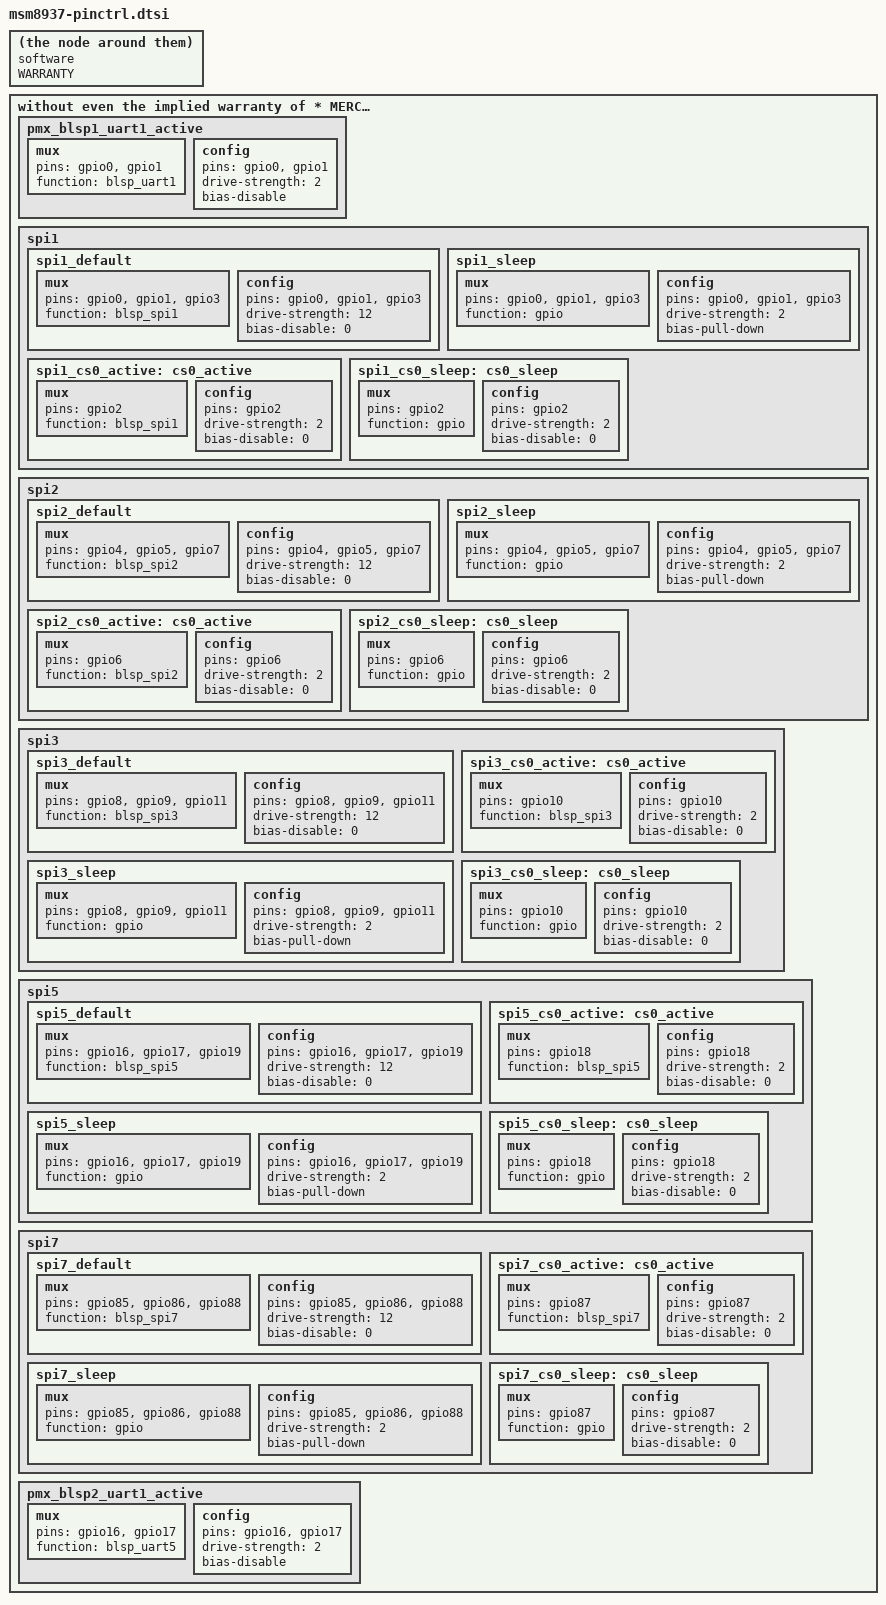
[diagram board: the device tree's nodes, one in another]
 * Copyright (c) 2015-2016, The Linux Foundation. All rights reserved.
 *
 * This program is free software; you can redistribute it and/or modify
 * it under the terms of the GNU General Public License version 2 and
 * only version 2 as published by the Free Software Foundation.
 *
 * This program is distributed in the hope that it will be useful,
 * but WITHOUT ANY WARRANTY; without even the implied warranty of
 * MERCHANTABILITY or FITNESS FOR A PARTICULAR PURPOSE.  See the
 * GNU General Public License for more details.
 */

&soc {
		pmx_blsp1_uart1_active: pmx_blsp1_uart1_active {
			mux {
				pins = "gpio0", "gpio1";
				function = "blsp_uart1";
			};

			config {
				pins = "gpio0", "gpio1";
				drive-strength = <2>;
				bias-disable;
			};
		};

		spi1 {
			spi1_default: spi1_default {
				/* active state */
				mux {
					/* MOSI, MISO, CLK */
					pins = "gpio0", "gpio1", "gpio3";
					function = "blsp_spi1";
				};

				config {
					pins = "gpio0", "gpio1", "gpio3";
					drive-strength = <12>; /* 12 MA */
					bias-disable = <0>; /* No PULL */
				};
			};

			spi1_sleep: spi1_sleep {
				/* suspended state */
				mux {
					/* MOSI, MISO, CLK */
					pins = "gpio0", "gpio1", "gpio3";
					function = "gpio";
				};

				config {
					pins = "gpio0", "gpio1", "gpio3";
					drive-strength = <2>; /* 2 MA */
					bias-pull-down; /* PULL Down */
				};
			};

			spi1_cs0_active: cs0_active {
				/* CS */
				mux {
					pins = "gpio2";
					function = "blsp_spi1";
				};

				config {
					pins = "gpio2";
					drive-strength = <2>;
					bias-disable = <0>;
				};
			};

			spi1_cs0_sleep: cs0_sleep {
				/* CS */
				mux {
					pins = "gpio2";
					function = "gpio";
				};

				config {
					pins = "gpio2";
					drive-strength = <2>;
					bias-disable = <0>;
				};
			};
		};

		spi2 {
			spi2_default: spi2_default {
				/* active state */
				mux {
					/* MOSI, MISO, CLK */
					pins = "gpio4", "gpio5", "gpio7";
					function = "blsp_spi2";
				};

				config {
					pins = "gpio4", "gpio5", "gpio7";
					drive-strength = <12>; /* 12 MA */
					bias-disable = <0>; /* No PULL */
				};
			};

			spi2_sleep: spi2_sleep {
				/* suspended state */
				mux {
					/* MOSI, MISO, CLK */
					pins = "gpio4", "gpio5", "gpio7";
					function = "gpio";
				};

				config {
					pins = "gpio4", "gpio5", "gpio7";
					drive-strength = <2>; /* 2 MA */
					bias-pull-down; /* PULL Down */
				};
			};

			spi2_cs0_active: cs0_active {
				/* CS */
				mux {
					pins = "gpio6";
					function = "blsp_spi2";
				};

				config {
					pins = "gpio6";
					drive-strength = <2>;
					bias-disable = <0>;
				};
			};

			spi2_cs0_sleep: cs0_sleep {
				/* CS */
				mux {
					pins = "gpio6";
					function = "gpio";
				};

				config {
					pins = "gpio6";
					drive-strength = <2>;
					bias-disable = <0>;
				};
			};
		};

		spi3 {
			spi3_default: spi3_default {
				/* active state */
				mux {
					/* MOSI, MISO, CLK */
					pins = "gpio8", "gpio9", "gpio11";
					function = "blsp_spi3";
				};

				config {
					pins = "gpio8", "gpio9", "gpio11";
					drive-strength = <12>; /* 12 MA */
					bias-disable = <0>; /* No PULL */
				};
			};

			spi3_sleep: spi3_sleep {
				/* suspended state */
				mux {
					/* MOSI, MISO, CLK */
					pins = "gpio8", "gpio9", "gpio11";
					function = "gpio";
				};

				config {
					pins = "gpio8", "gpio9", "gpio11";
					drive-strength = <2>; /* 2 MA */
					bias-pull-down; /* PULL Down */
				};
			};

			spi3_cs0_active: cs0_active {
				/* CS */
				mux {
					pins = "gpio10";
					function = "blsp_spi3";
				};

				config {
					pins = "gpio10";
					drive-strength = <2>;
					bias-disable = <0>;
				};
			};

			spi3_cs0_sleep: cs0_sleep {
				/* CS */
				mux {
					pins = "gpio10";
					function = "gpio";
				};

				config {
					pins = "gpio10";
					drive-strength = <2>;
					bias-disable = <0>;
				};
			};
		};

		spi5 {
			spi5_default: spi5_default {
				/* active state */
				mux {
					/* MOSI, MISO, CLK */
					pins = "gpio16", "gpio17", "gpio19";
					function = "blsp_spi5";
				};

				config {
					pins = "gpio16", "gpio17", "gpio19";
					drive-strength = <12>; /* 12 MA */
					bias-disable = <0>; /* No PULL */
				};
			};

			spi5_sleep: spi5_sleep {
				/* suspended state */
				mux {
					/* MOSI, MISO, CLK */
					pins = "gpio16", "gpio17", "gpio19";
					function = "gpio";
				};

				config {
					pins = "gpio16", "gpio17", "gpio19";
					drive-strength = <2>; /* 2 MA */
					bias-pull-down; /* PULL Down */
				};
			};

			spi5_cs0_active: cs0_active {
				/* CS */
				mux {
					pins = "gpio18";
					function = "blsp_spi5";
				};

				config {
					pins = "gpio18";
					drive-strength = <2>;
					bias-disable = <0>;
				};
			};

			spi5_cs0_sleep: cs0_sleep {
				/* CS */
				mux {
					pins = "gpio18";
					function = "gpio";
				};

				config {
					pins = "gpio18";
					drive-strength = <2>;
					bias-disable = <0>;
				};
			};
		};

		spi7 {
			spi7_default: spi7_default {
				/* active state */
				mux {
					/* MOSI, MISO, CLK */
					pins = "gpio85", "gpio86", "gpio88";
					function = "blsp_spi7";
				};

				config {
					pins = "gpio85", "gpio86", "gpio88";
					drive-strength = <12>; /* 12 MA */
					bias-disable = <0>; /* No PULL */
				};
			};

			spi7_sleep: spi7_sleep {
				/* suspended state */
				mux {
					/* MOSI, MISO, CLK */
					pins = "gpio85", "gpio86", "gpio88";
					function = "gpio";
				};

				config {
					pins = "gpio85", "gpio86", "gpio88";
					drive-strength = <2>; /* 2 MA */
					bias-pull-down; /* PULL Down */
				};
			};

			spi7_cs0_active: cs0_active {
				/* CS */
				mux {
					pins = "gpio87";
					function = "blsp_spi7";
				};

				config {
					pins = "gpio87";
					drive-strength = <2>;
					bias-disable = <0>;
				};
			};

			spi7_cs0_sleep: cs0_sleep {
				/* CS */
				mux {
					pins = "gpio87";
					function = "gpio";
				};

				config {
					pins = "gpio87";
					drive-strength = <2>;
					bias-disable = <0>;
				};
			};
		};

		pmx_blsp2_uart1_active: pmx_blsp2_uart1_active {
			mux {
				pins = "gpio16", "gpio17";
				function = "blsp_uart5";
			};

			config {
				pins = "gpio16", "gpio17";
				drive-strength = <2>;
				bias-disable;
			};
		};

};
